# riscv-virtio,qemu register map
File version: 0.1
From riscv-virtio,qemu,model device generator
Registers are 32-bit, read-write, reset 0x0 unless marked. A register's access mark holds for its fields unless they carry their own. Offsets are from the block's base; lines under a group give offsets from that group; [hi:lo] are bit positions; {n}, {i} and the like mark numbered series; 'fields as' and 'values as' point back to an identical list; <NAME> marks a mode.

## Memory map
0x02000000 clint size 0x10000 — RISC-V CLINT: clint
0x0C000000 plic size 0x600000 — RISC-V PLIC: plic
0x10000000 UART0 size 0x8 — NS16550A Compatible UART Peripheral

## plic — RISC-V PLIC: plic
Base 0x0C000000
{0x4+4i} priority[{i}] (i=0..94) — RISC-V PLIC Interrupt Source Priority.
  [31:0] priority — Represents interrupt source priority: `0` is reserved to mean `never interrupt`, and interrupt priority increases with increasing integer values.
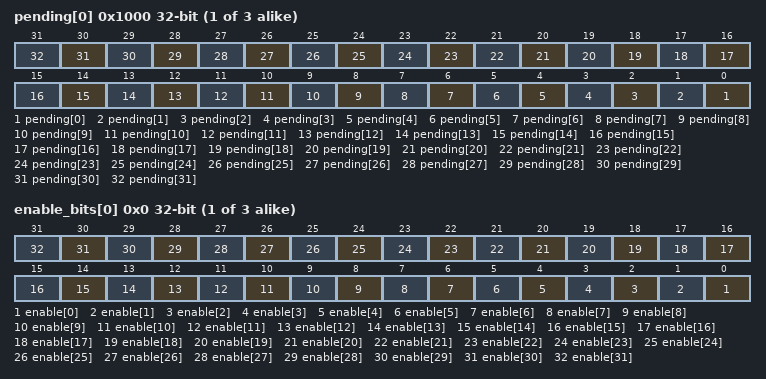
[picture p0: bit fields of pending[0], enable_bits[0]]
{0x1000+4i} pending[{i}] (i=0..2) — RISC-V PLIC Pending: 32-bit register indicating if there is a pending interrupt, e.g. pending[0][0] is interrupt 0, pending[0][31] is interrupt 31, pending[1][0] is interrupt 32.
  [n] pending[{n}] (n=0..31) — Bit index that indicates whether the interrupt source is pending
    0=clear (The interrupt source has no pending interrupt); 1=pending (The interrupt source has a pending interrupt)
{0x2000+0x80*i} enable[{i}] (i=0..0) group — PLIC interrupt enable registers (per-HART)
  {0x0+4j} enable_bits[{j}] (j=0..2) — Interrupt source enable bits.
    [n] enable[{n}] (n=0..31) — Enables the interrupt source associated with the bit index.
  0x7C _enable_reserved access not given — PLIC Enable Reserved register used for alignment.
{0x200000+0x1000*i} threshold_claim[{i}] (i=0..0) group — PLIC threshold and claim_complete registers
  0x00 threshold — Interrupt priority threshold of each context.
    [31:0] threshold — The PLIC will mask all PLIC interrupts of a priority less than or equal to `threshold`.
  0x04 claim_complete access per field — Interrupt source `claim` (read) and complete (write) register. The PLIC will write pending interrupt source information to the `claim` register. When the interrupt handler is finished, the interrupt source idendification should be written to the corresponding `complete` register.
    [31:0] claim ro — Claim interrupt source ID of highest-priority pending interrupt. Value of `0` indicates no pending interrupt.
    [31:0] complete wo — Completes handling for interrupt source ID.
  0xFFC _threshold_reserved access not given — PLIC Threshold Reserved register used for alignment.

## clint — RISC-V CLINT: clint
Base 0x02000000
{0x0+4i} msip[{i}] (i=0..0) — CLINT MSIP (Machine Software Interrupt) register
  [0] control
{0x4000+8i} mtimecmp[{i}] (i=0..0) 64-bit — CLINT MTIMECMP (Machine Time Compare) register
  [63:0] cycles
0xBFF8 mtime 64-bit — CLINT MTIME (Machine Time) register
  [63:0] cycles

## UART0 — NS16550A Compatible UART Peripheral
Base 0x10000000
0x00 RBR_THR_DLL 8-bit reset not defined — Rx Buffer (R), Tx Holding (W), or Divisor Latch Low (if DLAB=1)
0x01 IER_DLM 8-bit reset not defined — Interrupt Enable Register, or Divisor Latch High (if DLAB=1)
0x02 IIR_FCR 8-bit reset not defined — Interrupt Identification Register (R) or FIFO Control Register (W)
0x03 LCR 8-bit reset not defined — Line Control Register (Bit 7 is DLAB)
  [7] DLAB — Divisor Latch Access Bit
0x04 MCR 8-bit reset not defined — Modem Control Register
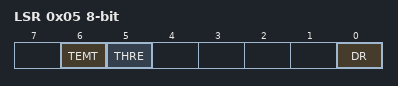
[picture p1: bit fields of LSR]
0x05 LSR 8-bit ro reset not defined — Line Status Register
  [6] TEMT — Transmitter Empty
  [5] THRE — Tx Holding Register Empty
  [0] DR — Data Ready
0x06 MSR 8-bit ro reset not defined — Modem Status Register
0x07 SCR 8-bit reset not defined — Scratchpad Register
